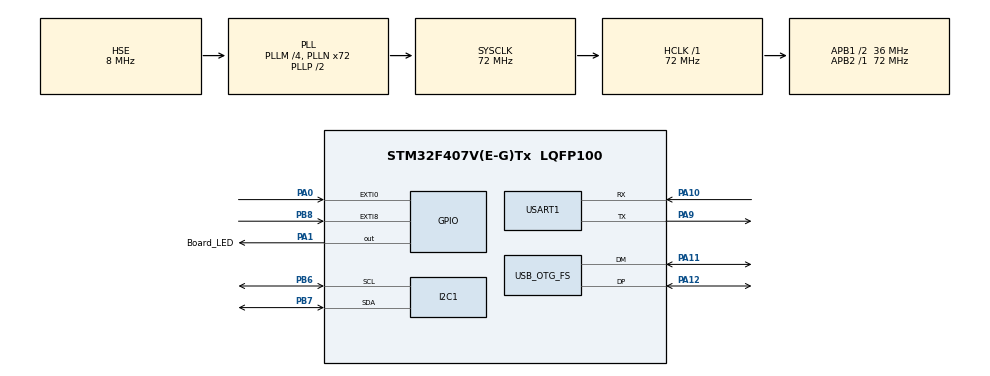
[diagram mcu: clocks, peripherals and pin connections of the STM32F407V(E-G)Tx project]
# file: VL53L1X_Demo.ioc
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Mcu.Family=STM32F4
Mcu.Name=STM32F407V(E-G)Tx
Mcu.Package=LQFP100
NVIC.OTG_FS_IRQn=true\:0\:0\:false\:false\:true\:false\:true\:true
NVIC.PriorityGroup=NVIC_PRIORITYGROUP_4
PA0-WKUP.Signal=GPXTI0
PA1.GPIO_Label=Board_LED
PA1.Signal=GPIO_Output
PA10.Mode=Asynchronous
PA10.Signal=USART1_RX
PA11.Mode=Device_Only
PA11.Signal=USB_OTG_FS_DM
PA12.Mode=Device_Only
PA12.Signal=USB_OTG_FS_DP
PA13.Mode=Serial_Wire
PA13.Signal=SYS_JTMS-SWDIO
PA14.Mode=Serial_Wire
PA14.Signal=SYS_JTCK-SWCLK
PA9.Mode=Asynchronous
PA9.Signal=USART1_TX
PB6.Mode=I2C
PB6.Signal=I2C1_SCL
PB7.Mode=I2C
PB7.Signal=I2C1_SDA
PB8.Signal=GPXTI8
PH0-OSC_IN.Mode=HSE-External-Oscillator
PH0-OSC_IN.Signal=RCC_OSC_IN
PH1-OSC_OUT.Mode=HSE-External-Oscillator
PH1-OSC_OUT.Signal=RCC_OSC_OUT
ProjectManager.HeapSize=0x200
ProjectManager.StackSize=0x400
ProjectManager.TargetToolchain=MDK-ARM V5.32
RCC.48MHZClocksFreq_Value=48000000
RCC.AHBFreq_Value=72000000
RCC.APB1CLKDivider=RCC_HCLK_DIV2
RCC.APB1Freq_Value=36000000
RCC.APB1TimFreq_Value=72000000
RCC.APB2Freq_Value=72000000
RCC.APB2TimFreq_Value=72000000
RCC.CortexFreq_Value=72000000
RCC.HCLKFreq_Value=72000000
RCC.HSE_VALUE=8000000
RCC.HSI_VALUE=16000000
RCC.LSE_VALUE=32768
RCC.PLLM=4
RCC.PLLN=72
RCC.PLLQ=3
RCC.SYSCLKFreq_VALUE=72000000
RCC.SYSCLKSource=RCC_SYSCLKSOURCE_PLLCLK
RCC.VCOOutputFreq_Value=144000000
USART1.VirtualMode=VM_ASYNC
USB_DEVICE.CLASS_NAME_FS=CDC
USB_DEVICE.VirtualMode-CDC_FS=Cdc
USB_DEVICE.VirtualModeFS=Cdc_FS
USB_OTG_FS.VirtualMode=Device_Only
VP_USB_DEVICE_VS_USB_DEVICE_CDC_FS.Mode=CDC_FS
board=custom

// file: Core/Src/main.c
/* USER CODE BEGIN Header */
/**
 ******************************************************************************
 * @file           : main.c
 * @brief          : Main program body
 ******************************************************************************
 * @attention
 *
 * Copyright (c) 2024 STMicroelectronics.
 * All rights reserved.
 *
 * This software is licensed under terms that can be found in the LICENSE file
 * in the root directory of this software component.
 * If no LICENSE file comes with this software, it is provided AS-IS.
 *
 ******************************************************************************
 */
/* USER CODE END Header */
#include "main.h"
#include "usb_device.h"

/* USER CODE BEGIN Includes */
#include <errno.h>
#include <sys/unistd.h> // STDOUT_FILENO, STDERR_FILENO
#include "usbd_cdc_if.h"
#include "app_main.h"
/* USER CODE END Includes */

I2C_HandleTypeDef hi2c1;

UART_HandleTypeDef huart1;

void SystemClock_Config(void);
static void MX_GPIO_Init(void);
static void MX_I2C1_Init(void);
static void MX_USART1_UART_Init(void);

/* USER CODE BEGIN 0 */
int _write(int file, char *data, int len)
{
  if ((file != STDOUT_FILENO) && (file != STDERR_FILENO))
  {
    errno = EBADF;
    return -1;
  }

  HAL_StatusTypeDef status =
      CDC_Transmit_FS((uint8_t *)data, len);

  // return # of bytes written - as best we can tell
  return (status == HAL_OK ? len : 0);
}
/* USER CODE END 0 */

int main(void)
{

  /* MCU Configuration--------------------------------------------------------*/

  /* Reset of all peripherals, Initializes the Flash interface and the Systick. */
  HAL_Init();

  /* Configure the system clock */
  SystemClock_Config();

  /* Initialize all configured peripherals */
  MX_GPIO_Init();
  MX_USB_DEVICE_Init();
  MX_I2C1_Init();
  MX_USART1_UART_Init();

  /* Infinite loop */
  /* USER CODE BEGIN WHILE */
  app_main_init();
  while (1)
  {
    app_main_loop();
    /* USER CODE END WHILE */

  }
}

void SystemClock_Config(void)
{
  RCC_OscInitTypeDef RCC_OscInitStruct = {0};
  RCC_ClkInitTypeDef RCC_ClkInitStruct = {0};

  /** Configure the main internal regulator output voltage
   */
  __HAL_RCC_PWR_CLK_ENABLE();
  __HAL_PWR_VOLTAGESCALING_CONFIG(PWR_REGULATOR_VOLTAGE_SCALE1);

  /** Initializes the RCC Oscillators according to the specified parameters
   * in the RCC_OscInitTypeDef structure.
   */
  RCC_OscInitStruct.OscillatorType = RCC_OSCILLATORTYPE_HSE;
  RCC_OscInitStruct.HSEState = RCC_HSE_ON;
  RCC_OscInitStruct.PLL.PLLState = RCC_PLL_ON;
  RCC_OscInitStruct.PLL.PLLSource = RCC_PLLSOURCE_HSE;
  RCC_OscInitStruct.PLL.PLLM = 4;
  RCC_OscInitStruct.PLL.PLLN = 72;
  RCC_OscInitStruct.PLL.PLLP = RCC_PLLP_DIV2;
  RCC_OscInitStruct.PLL.PLLQ = 3;
  if (HAL_RCC_OscConfig(&RCC_OscInitStruct) != HAL_OK)
  {
    Error_Handler();
  }

  /** Initializes the CPU, AHB and APB buses clocks
   */
  RCC_ClkInitStruct.ClockType = RCC_CLOCKTYPE_HCLK | RCC_CLOCKTYPE_SYSCLK | RCC_CLOCKTYPE_PCLK1 | RCC_CLOCKTYPE_PCLK2;
  RCC_ClkInitStruct.SYSCLKSource = RCC_SYSCLKSOURCE_PLLCLK;
  RCC_ClkInitStruct.AHBCLKDivider = RCC_SYSCLK_DIV1;
  RCC_ClkInitStruct.APB1CLKDivider = RCC_HCLK_DIV2;
  RCC_ClkInitStruct.APB2CLKDivider = RCC_HCLK_DIV1;

  if (HAL_RCC_ClockConfig(&RCC_ClkInitStruct, FLASH_LATENCY_2) != HAL_OK)
  {
    Error_Handler();
  }
}

static void MX_I2C1_Init(void)
{

  hi2c1.Instance = I2C1;
  hi2c1.Init.ClockSpeed = 100000;
  hi2c1.Init.DutyCycle = I2C_DUTYCYCLE_2;
  hi2c1.Init.OwnAddress1 = 0;
  hi2c1.Init.AddressingMode = I2C_ADDRESSINGMODE_7BIT;
  hi2c1.Init.DualAddressMode = I2C_DUALADDRESS_DISABLE;
  hi2c1.Init.OwnAddress2 = 0;
  hi2c1.Init.GeneralCallMode = I2C_GENERALCALL_DISABLE;
  hi2c1.Init.NoStretchMode = I2C_NOSTRETCH_DISABLE;
  if (HAL_I2C_Init(&hi2c1) != HAL_OK)
  {
    Error_Handler();
  }
}

static void MX_USART1_UART_Init(void)
{

  huart1.Instance = USART1;
  huart1.Init.BaudRate = 115200;
  huart1.Init.WordLength = UART_WORDLENGTH_8B;
  huart1.Init.StopBits = UART_STOPBITS_1;
  huart1.Init.Parity = UART_PARITY_NONE;
  huart1.Init.Mode = UART_MODE_TX_RX;
  huart1.Init.HwFlowCtl = UART_HWCONTROL_NONE;
  huart1.Init.OverSampling = UART_OVERSAMPLING_16;
  if (HAL_UART_Init(&huart1) != HAL_OK)
  {
    Error_Handler();
  }
}

static void MX_GPIO_Init(void)
{
  GPIO_InitTypeDef GPIO_InitStruct = {0};

  /* GPIO Ports Clock Enable */
  __HAL_RCC_GPIOH_CLK_ENABLE();
  __HAL_RCC_GPIOA_CLK_ENABLE();
  __HAL_RCC_GPIOB_CLK_ENABLE();

  /*Configure GPIO pin Output Level */
  HAL_GPIO_WritePin(Board_LED_GPIO_Port, Board_LED_Pin, GPIO_PIN_RESET);

  /*Configure GPIO pin : PA0 */
  GPIO_InitStruct.Pin = GPIO_PIN_0;
  GPIO_InitStruct.Mode = GPIO_MODE_IT_RISING;
  GPIO_InitStruct.Pull = GPIO_NOPULL;
  HAL_GPIO_Init(GPIOA, &GPIO_InitStruct);

  /*Configure GPIO pin : Board_LED_Pin */
  GPIO_InitStruct.Pin = Board_LED_Pin;
  GPIO_InitStruct.Mode = GPIO_MODE_OUTPUT_PP;
  GPIO_InitStruct.Pull = GPIO_NOPULL;
  GPIO_InitStruct.Speed = GPIO_SPEED_FREQ_LOW;
  HAL_GPIO_Init(Board_LED_GPIO_Port, &GPIO_InitStruct);

  /*Configure GPIO pin : PB8 */
  GPIO_InitStruct.Pin = GPIO_PIN_8;
  GPIO_InitStruct.Mode = GPIO_MODE_IT_RISING;
  GPIO_InitStruct.Pull = GPIO_NOPULL;
  HAL_GPIO_Init(GPIOB, &GPIO_InitStruct);

}

void Error_Handler(void)
{
  __disable_irq();
  while (1)
  {
  }
}
